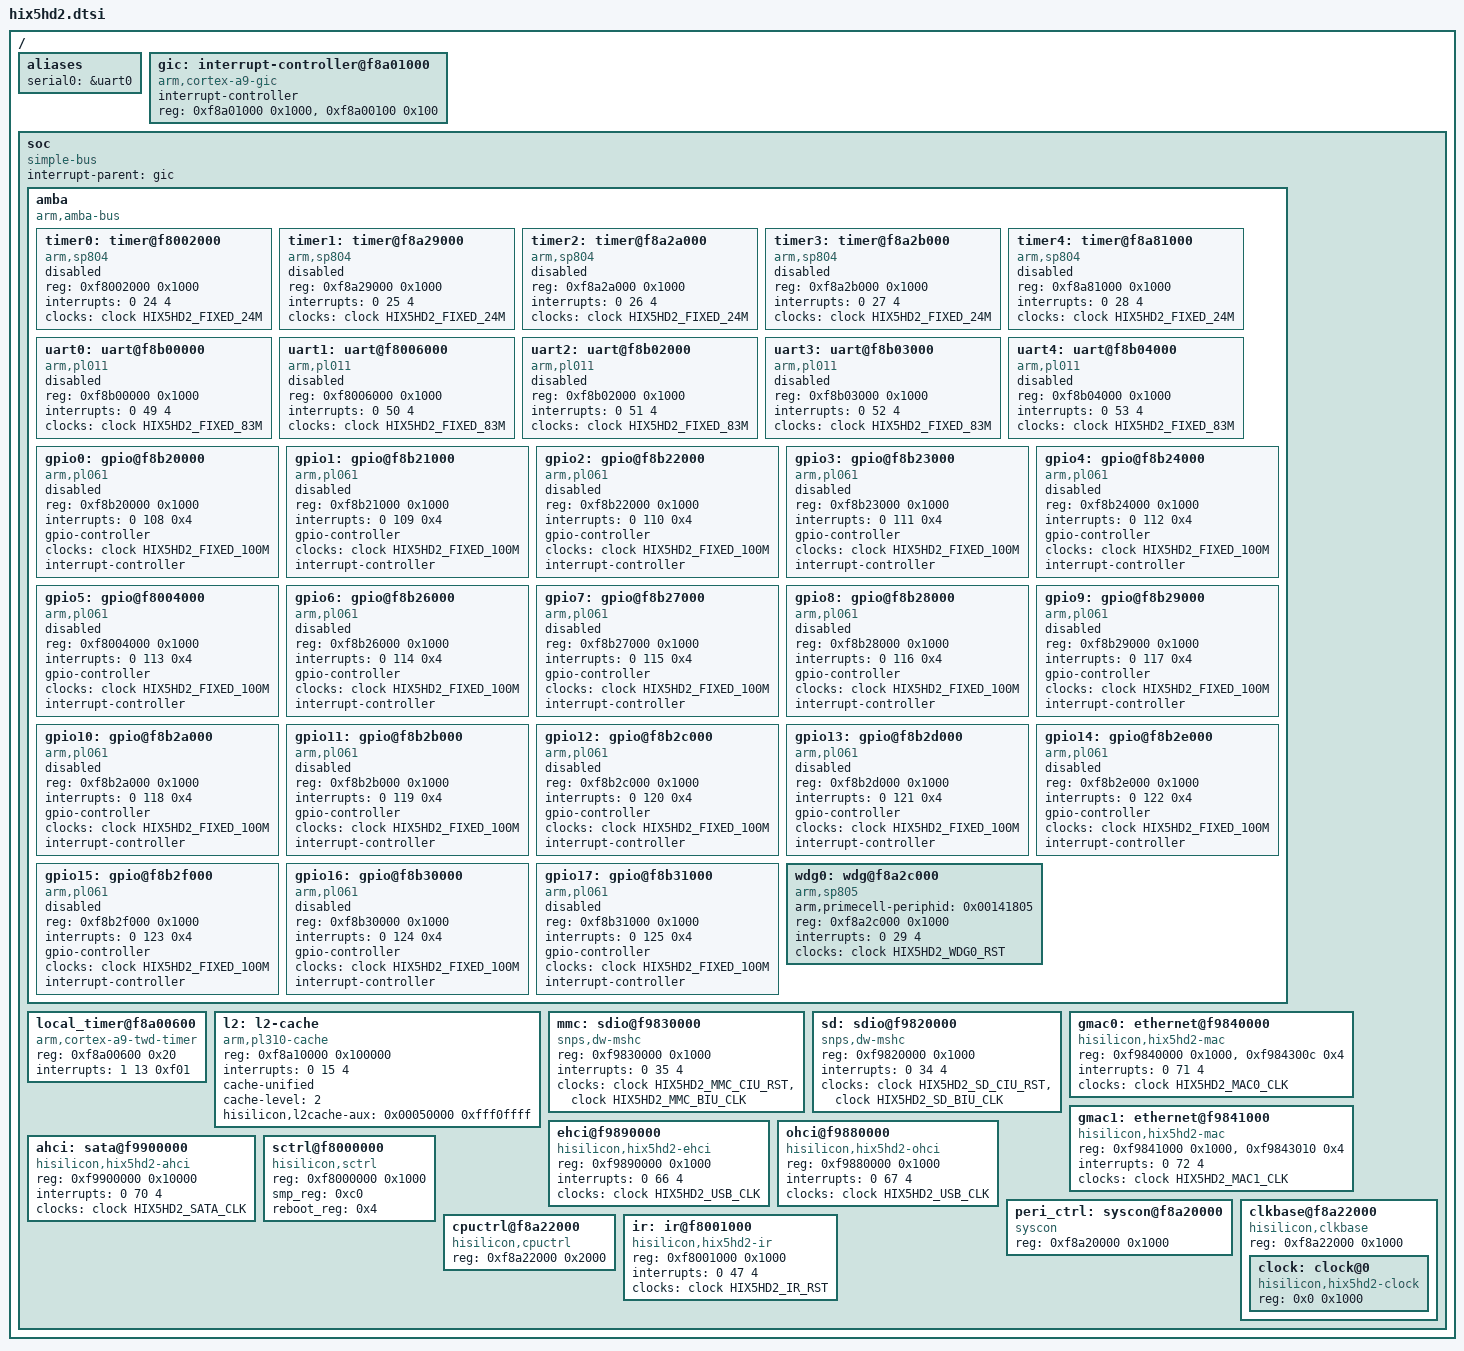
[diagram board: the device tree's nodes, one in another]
/*
 * Copyright (c) 2013 Linaro Ltd.
 * Copyright (c) 2013 Hisilicon Limited.
 *
 * This program is free software; you can redistribute it and/or modify
 * it under the terms of the GNU General Public License version 2 as
 * publishhed by the Free Software Foundation.
 */

#include "skeleton.dtsi"
#include <dt-bindings/clock/hix5hd2-clock.h>

/ {
	aliases {
		serial0 = &uart0;
	};

	gic: interrupt-controller@f8a01000 {
		compatible = "arm,cortex-a9-gic";
		#interrupt-cells = <3>;
		#address-cells = <0>;
		interrupt-controller;
		/* gic dist base, gic cpu base */
		reg = <0xf8a01000 0x1000>, <0xf8a00100 0x100>;
	};

	soc {
		#address-cells = <1>;
		#size-cells = <1>;
		compatible = "simple-bus";
		device_type = "soc";
		interrupt-parent = <&gic>;
		ranges;

		amba {
			#address-cells = <1>;
			#size-cells = <1>;
			compatible = "arm,amba-bus";
			ranges;

			timer0: timer@f8002000 {
				compatible = "arm,sp804", "arm,primecell";
				reg = <0xf8002000 0x1000>;
				/* timer00 & timer01 */
				interrupts = <0 24 4>;
				clocks = <&clock HIX5HD2_FIXED_24M>;
				status = "disabled";
			};

			timer1: timer@f8a29000 {
				/*
				 * Only used in NORMAL state, not available ins
				 * SLOW or DOZE state.
				 * The rate is fixed in 24MHz.
				 */
				compatible = "arm,sp804", "arm,primecell";
				reg = <0xf8a29000 0x1000>;
				/* timer10 & timer11 */
				interrupts = <0 25 4>;
				clocks = <&clock HIX5HD2_FIXED_24M>;
				status = "disabled";
			};

			timer2: timer@f8a2a000 {
				compatible = "arm,sp804", "arm,primecell";
				reg = <0xf8a2a000 0x1000>;
				/* timer20 & timer21 */
				interrupts = <0 26 4>;
				clocks = <&clock HIX5HD2_FIXED_24M>;
				status = "disabled";
			};

			timer3: timer@f8a2b000 {
				compatible = "arm,sp804", "arm,primecell";
				reg = <0xf8a2b000 0x1000>;
				/* timer30 & timer31 */
				interrupts = <0 27 4>;
				clocks = <&clock HIX5HD2_FIXED_24M>;
				status = "disabled";
			};

			timer4: timer@f8a81000 {
				compatible = "arm,sp804", "arm,primecell";
				reg = <0xf8a81000 0x1000>;
				/* timer30 & timer31 */
				interrupts = <0 28 4>;
				clocks = <&clock HIX5HD2_FIXED_24M>;
				status = "disabled";
			};

			uart0: uart@f8b00000 {
				compatible = "arm,pl011", "arm,primecell";
				reg = <0xf8b00000 0x1000>;
				interrupts = <0 49 4>;
				clocks = <&clock HIX5HD2_FIXED_83M>;
				clock-names = "apb_pclk";
				status = "disabled";
			};

			uart1: uart@f8006000 {
				compatible = "arm,pl011", "arm,primecell";
				reg = <0xf8006000 0x1000>;
				interrupts = <0 50 4>;
				clocks = <&clock HIX5HD2_FIXED_83M>;
				clock-names = "apb_pclk";
				status = "disabled";
			};

			uart2: uart@f8b02000 {
				compatible = "arm,pl011", "arm,primecell";
				reg = <0xf8b02000 0x1000>;
				interrupts = <0 51 4>;
				clocks = <&clock HIX5HD2_FIXED_83M>;
				clock-names = "apb_pclk";
				status = "disabled";
			};

			uart3: uart@f8b03000 {
				compatible = "arm,pl011", "arm,primecell";
				reg = <0xf8b03000 0x1000>;
				interrupts = <0 52 4>;
				clocks = <&clock HIX5HD2_FIXED_83M>;
				clock-names = "apb_pclk";
				status = "disabled";
			};

			uart4: uart@f8b04000 {
				compatible = "arm,pl011", "arm,primecell";
				reg = <0xf8b04000 0x1000>;
				interrupts = <0 53 4>;
				clocks = <&clock HIX5HD2_FIXED_83M>;
				clock-names = "apb_pclk";
				status = "disabled";
			};

			gpio0: gpio@f8b20000 {
                                compatible = "arm,pl061", "arm,primecell";
                                reg = <0xf8b20000 0x1000>;
                                interrupts = <0 108 0x4>;
                                gpio-controller;
                                #gpio-cells = <2>;
				clocks = <&clock HIX5HD2_FIXED_100M>;
				clock-names = "apb_pclk";
                                interrupt-controller;
                                #interrupt-cells = <2>;
                                status = "disabled";
                        };

			gpio1: gpio@f8b21000 {
                                compatible = "arm,pl061", "arm,primecell";
                                reg = <0xf8b21000 0x1000>;
                                interrupts = <0 109 0x4>;
                                gpio-controller;
                                #gpio-cells = <2>;
				clocks = <&clock HIX5HD2_FIXED_100M>;
				clock-names = "apb_pclk";
                                interrupt-controller;
                                #interrupt-cells = <2>;
                                status = "disabled";
                        };

			gpio2: gpio@f8b22000 {
                                compatible = "arm,pl061", "arm,primecell";
                                reg = <0xf8b22000 0x1000>;
                                interrupts = <0 110 0x4>;
                                gpio-controller;
                                #gpio-cells = <2>;
				clocks = <&clock HIX5HD2_FIXED_100M>;
				clock-names = "apb_pclk";
                                interrupt-controller;
                                #interrupt-cells = <2>;
                                status = "disabled";
                        };

			gpio3: gpio@f8b23000 {
                                compatible = "arm,pl061", "arm,primecell";
                                reg = <0xf8b23000 0x1000>;
                                interrupts = <0 111 0x4>;
                                gpio-controller;
                                #gpio-cells = <2>;
				clocks = <&clock HIX5HD2_FIXED_100M>;
				clock-names = "apb_pclk";
                                interrupt-controller;
                                #interrupt-cells = <2>;
                                status = "disabled";
                        };

			gpio4: gpio@f8b24000 {
                                compatible = "arm,pl061", "arm,primecell";
                                reg = <0xf8b24000 0x1000>;
                                interrupts = <0 112 0x4>;
                                gpio-controller;
                                #gpio-cells = <2>;
				clocks = <&clock HIX5HD2_FIXED_100M>;
				clock-names = "apb_pclk";
                                interrupt-controller;
                                #interrupt-cells = <2>;
                                status = "disabled";
                        };

			gpio5: gpio@f8004000 {
                                compatible = "arm,pl061", "arm,primecell";
                                reg = <0xf8004000 0x1000>;
                                interrupts = <0 113 0x4>;
                                gpio-controller;
                                #gpio-cells = <2>;
				clocks = <&clock HIX5HD2_FIXED_100M>;
				clock-names = "apb_pclk";
                                interrupt-controller;
                                #interrupt-cells = <2>;
                                status = "disabled";
                        };

			gpio6: gpio@f8b26000 {
                                compatible = "arm,pl061", "arm,primecell";
                                reg = <0xf8b26000 0x1000>;
                                interrupts = <0 114 0x4>;
                                gpio-controller;
                                #gpio-cells = <2>;
				clocks = <&clock HIX5HD2_FIXED_100M>;
				clock-names = "apb_pclk";
                                interrupt-controller;
                                #interrupt-cells = <2>;
                                status = "disabled";
                        };

			gpio7: gpio@f8b27000 {
                                compatible = "arm,pl061", "arm,primecell";
                                reg = <0xf8b27000 0x1000>;
                                interrupts = <0 115 0x4>;
                                gpio-controller;
                                #gpio-cells = <2>;
				clocks = <&clock HIX5HD2_FIXED_100M>;
				clock-names = "apb_pclk";
                                interrupt-controller;
                                #interrupt-cells = <2>;
                                status = "disabled";
                        };

			gpio8: gpio@f8b28000 {
                                compatible = "arm,pl061", "arm,primecell";
                                reg = <0xf8b28000 0x1000>;
                                interrupts = <0 116 0x4>;
                                gpio-controller;
                                #gpio-cells = <2>;
				clocks = <&clock HIX5HD2_FIXED_100M>;
				clock-names = "apb_pclk";
                                interrupt-controller;
                                #interrupt-cells = <2>;
                                status = "disabled";
                        };

			gpio9: gpio@f8b29000 {
                                compatible = "arm,pl061", "arm,primecell";
                                reg = <0xf8b29000 0x1000>;
                                interrupts = <0 117 0x4>;
                                gpio-controller;
                                #gpio-cells = <2>;
				clocks = <&clock HIX5HD2_FIXED_100M>;
				clock-names = "apb_pclk";
                                interrupt-controller;
                                #interrupt-cells = <2>;
                                status = "disabled";
                        };

			gpio10: gpio@f8b2a000 {
                                compatible = "arm,pl061", "arm,primecell";
                                reg = <0xf8b2a000 0x1000>;
                                interrupts = <0 118 0x4>;
                                gpio-controller;
                                #gpio-cells = <2>;
				clocks = <&clock HIX5HD2_FIXED_100M>;
				clock-names = "apb_pclk";
                                interrupt-controller;
                                #interrupt-cells = <2>;
                                status = "disabled";
                        };

			gpio11: gpio@f8b2b000 {
                                compatible = "arm,pl061", "arm,primecell";
                                reg = <0xf8b2b000 0x1000>;
                                interrupts = <0 119 0x4>;
                                gpio-controller;
                                #gpio-cells = <2>;
				clocks = <&clock HIX5HD2_FIXED_100M>;
				clock-names = "apb_pclk";
                                interrupt-controller;
                                #interrupt-cells = <2>;
                                status = "disabled";
                        };

			gpio12: gpio@f8b2c000 {
                                compatible = "arm,pl061", "arm,primecell";
                                reg = <0xf8b2c000 0x1000>;
                                interrupts = <0 120 0x4>;
                                gpio-controller;
                                #gpio-cells = <2>;
				clocks = <&clock HIX5HD2_FIXED_100M>;
				clock-names = "apb_pclk";
                                interrupt-controller;
                                #interrupt-cells = <2>;
                                status = "disabled";
                        };

			gpio13: gpio@f8b2d000 {
                                compatible = "arm,pl061", "arm,primecell";
                                reg = <0xf8b2d000 0x1000>;
                                interrupts = <0 121 0x4>;
                                gpio-controller;
                                #gpio-cells = <2>;
				clocks = <&clock HIX5HD2_FIXED_100M>;
				clock-names = "apb_pclk";
                                interrupt-controller;
                                #interrupt-cells = <2>;
                                status = "disabled";
                        };

			gpio14: gpio@f8b2e000 {
                                compatible = "arm,pl061", "arm,primecell";
                                reg = <0xf8b2e000 0x1000>;
                                interrupts = <0 122 0x4>;
                                gpio-controller;
                                #gpio-cells = <2>;
				clocks = <&clock HIX5HD2_FIXED_100M>;
				clock-names = "apb_pclk";
                                interrupt-controller;
                                #interrupt-cells = <2>;
                                status = "disabled";
                        };

			gpio15: gpio@f8b2f000 {
                                compatible = "arm,pl061", "arm,primecell";
                                reg = <0xf8b2f000 0x1000>;
                                interrupts = <0 123 0x4>;
                                gpio-controller;
                                #gpio-cells = <2>;
				clocks = <&clock HIX5HD2_FIXED_100M>;
				clock-names = "apb_pclk";
                                interrupt-controller;
                                #interrupt-cells = <2>;
                                status = "disabled";
                        };

			gpio16: gpio@f8b30000 {
                                compatible = "arm,pl061", "arm,primecell";
                                reg = <0xf8b30000 0x1000>;
                                interrupts = <0 124 0x4>;
                                gpio-controller;
                                #gpio-cells = <2>;
				clocks = <&clock HIX5HD2_FIXED_100M>;
				clock-names = "apb_pclk";
                                interrupt-controller;
                                #interrupt-cells = <2>;
                                status = "disabled";
                        };

			gpio17: gpio@f8b31000 {
                                compatible = "arm,pl061", "arm,primecell";
                                reg = <0xf8b31000 0x1000>;
                                interrupts = <0 125 0x4>;
                                gpio-controller;
                                #gpio-cells = <2>;
				clocks = <&clock HIX5HD2_FIXED_100M>;
				clock-names = "apb_pclk";
                                interrupt-controller;
                                #interrupt-cells = <2>;
                                status = "disabled";
                        };
			wdg0: wdg@f8a2c000 {
				compatible = "arm,sp805", "arm,primecell";
				arm,primecell-periphid = <0x00141805>;
				reg = <0xf8a2c000 0x1000>;
				interrupts = <0 29 4>;
				clocks = <&clock  HIX5HD2_WDG0_RST>;
				clock-names = "apb_pclk";
                       };
		};

		local_timer@f8a00600 {
			compatible = "arm,cortex-a9-twd-timer";
			reg = <0xf8a00600 0x20>;
			interrupts = <1 13 0xf01>;
		};

		l2: l2-cache {
			compatible = "arm,pl310-cache";
			reg = <0xf8a10000 0x100000>;
			interrupts = <0 15 4>;
			cache-unified;
			cache-level = <2>;
			hisilicon,l2cache-aux = <0x00050000 0xfff0ffff>;
		};

		/* unremovable emmc as mmcblk0 */
		mmc:sdio@f9830000 {
			compatible = "snps,dw-mshc";
			reg = <0xf9830000 0x1000>;
			interrupts = <0 35 4>;
			#address-cells = <1>;
			#size-cells = <0>;
			clocks = <&clock HIX5HD2_MMC_CIU_RST>, <&clock HIX5HD2_MMC_BIU_CLK>;
			clock-names = "ciu", "biu";
		};

		sd:sdio@f9820000 {
			compatible = "snps,dw-mshc";
			reg = <0xf9820000 0x1000>;
			interrupts = <0 34 4>;
			#address-cells = <1>;
			#size-cells = <0>;
			clocks = <&clock HIX5HD2_SD_CIU_RST>,<&clock HIX5HD2_SD_BIU_CLK>;
			clock-names = "ciu","biu";
		};

		gmac0: ethernet@f9840000 {
			compatible = "hisilicon,hix5hd2-mac";
			reg = <0xf9840000 0x1000>,<0xf984300c 0x4>;
			interrupts = <0 71 4>;
			clocks = <&clock HIX5HD2_MAC0_CLK>;
		};

		gmac1: ethernet@f9841000 {
			compatible = "hisilicon,hix5hd2-mac";
			reg = <0xf9841000 0x1000>,<0xf9843010 0x4>;
			interrupts = <0 72 4>;
			clocks = <&clock HIX5HD2_MAC1_CLK>;
		};

		ehci@f9890000 {
		        compatible = "hisilicon,hix5hd2-ehci","generic-ehci";
			reg = <0xf9890000 0x1000>;
			interrupts = <0 66 4>;
			clocks = <&clock HIX5HD2_USB_CLK>;
	        };

		ohci@f9880000 {
			compatible = "hisilicon,hix5hd2-ohci","generic-ohci";
			reg = <0xf9880000 0x1000>;
			interrupts = <0 67 4>;
			clocks = <&clock HIX5HD2_USB_CLK>;
		};

		ahci:sata@f9900000 {
                        compatible = "hisilicon,hix5hd2-ahci";
                        reg = <0xf9900000 0x10000>;
                        interrupts = <0 70 4>;
                        clocks = <&clock HIX5HD2_SATA_CLK>;
		};

		sctrl@f8000000 {
			compatible = "hisilicon,sctrl";
			reg = <0xf8000000 0x1000>;
			smp_reg = <0xc0>;
			reboot_reg = <0x4>;
		};

		peri_ctrl:syscon@f8a20000 {
			compatible = "syscon";
			reg = <0xf8a20000 0x1000>;
		};

		clkbase@f8a22000 {
			compatible = "hisilicon,clkbase";
			#address-cells = <1>;
			#size-cells = <1>;
			reg = <0xf8a22000 0x1000>;
			ranges = <0x0 0xf8a22000 0x1000>;
			clock: clock@0 {
				compatible = "hisilicon,hix5hd2-clock";
				reg = <0x0 0x1000>;
				#clock-cells = <1>;
			};
		};

		cpuctrl@f8a22000 {
			compatible = "hisilicon,cpuctrl";
			reg = <0xf8a22000 0x2000>;
		};

		ir: ir@f8001000 {
			compatible = "hisilicon,hix5hd2-ir";
			reg = <0xf8001000 0x1000>;
			interrupts = <0 47 4>;
			clocks = <&clock  HIX5HD2_IR_RST>;
        	};
	};
};
